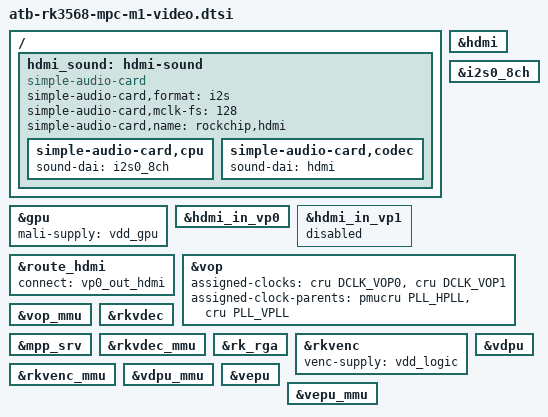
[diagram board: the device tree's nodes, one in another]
#include <dt-bindings/display/rockchip_vop.h>

/{
	hdmi_sound: hdmi-sound {
		compatible = "simple-audio-card";
		simple-audio-card,format = "i2s";
		simple-audio-card,mclk-fs = <128>;
		simple-audio-card,name = "rockchip,hdmi";
		status = "okay";

		simple-audio-card,cpu {
				sound-dai = <&i2s0_8ch>;
		};
		simple-audio-card,codec {
				sound-dai = <&hdmi>;
		};
	};
};

&gpu {
	mali-supply = <&vdd_gpu>;
	status = "okay";
};

&hdmi {
	status = "okay";
};

&hdmi_in_vp0 {
	status = "okay";
};

&hdmi_in_vp1 {
	status = "disabled";
};

&route_hdmi {
	status = "okay";
	connect = <&vp0_out_hdmi>;
};

&hdmi_sound {
	status = "okay";
};

&i2s0_8ch {
	// hdmi sound
	status = "okay";
};

&vop {
	status = "okay";
	assigned-clocks = <&cru DCLK_VOP0>, <&cru DCLK_VOP1>;
	assigned-clock-parents = <&pmucru PLL_HPLL>, <&cru PLL_VPLL>;
};

&vop_mmu {
	status = "okay";
};

//------------------------------------------------------------------------------
&mpp_srv {
	status = "okay";
};

&rkvdec {
	status = "okay";
};

&rkvdec_mmu {
	status = "okay";
};

&rk_rga {
	status = "okay";
};

&rkvenc {
	venc-supply = <&vdd_logic>;
	status = "okay";
};

&rkvenc_mmu {
	status = "okay";
};

&vdpu {
	status = "okay";
};

&vdpu_mmu {
	status = "okay";
};

&vepu {
	status = "okay";
};

&vepu_mmu {
	status = "okay";
};
